# NUC122_v1 register map
File version: 1.0
Registers are 32-bit, read-write, reset 0x0 unless marked. A register's access mark holds for its fields unless they carry their own. Offsets are from the block's base; [hi:lo] are bit positions.

## RTC — RTC Register Map
Base 0x40008000
0x00 INIR — RTC Initiation Register
  [31:0] INIR — RTC Initiation. Read return current RTC active status. A write of 0xa5eb1357 to make RTC leaving reset state. When RTC block is powered on, RTC is in reset state. User has to write a number 0x a5eb1357 to INIR register to make RTC leave reset state. Once the INIR is written as 0xa5eb1357, the RTC will be in normal active state permanently.
    0=RTC is in reset state; 1=RTC is in normal active state
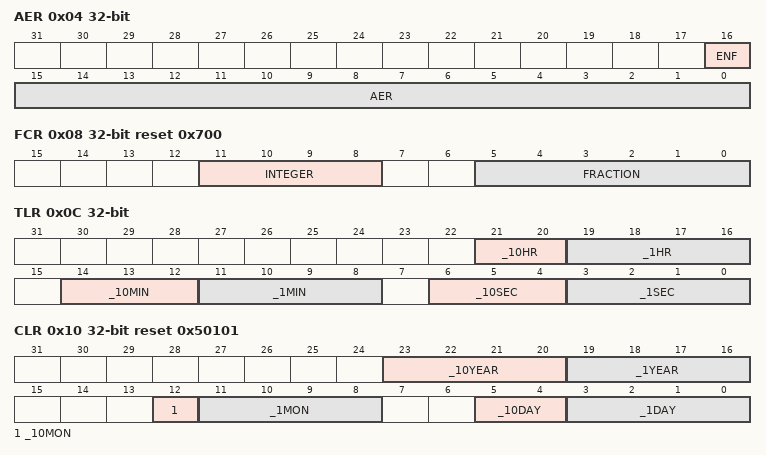
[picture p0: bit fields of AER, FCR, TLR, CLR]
0x04 AER — RTC Access Enable Register
  [16] ENF ro — RTC Register Access Enable Flag (Read only)
    0=RTC register read/write disable; 1=RTC register read/write enable
  [15:0] AER wo — RTC Register Access Enable Password (Write only). Writing 0xA965 to this register will enable RTC registers read/write access and keep 512 RTC clocks.
0x08 FCR reset 0x700 — Frequency Compensation Register
  [11:8] INTEGER — Integer Part
  [5:0] FRACTION — Fraction Part. Note: Digit in FCR must be expressed as hexadecimal number. Refer to 5.8.4.4 for the examples.
0x0C TLR — Time Loading Register
  [21:20] _10HR — 10-Hour Time Digit (0~2)
  [19:16] _1HR — 1-Hour Time Digit (0~9)
  [14:12] _10MIN — 10-Min Time Digit (0~5)
  [11:8] _1MIN — 1-Min Time Digit (0~9)
  [6:4] _10SEC — 10-Sec Time Digit (0~5)
  [3:0] _1SEC — 1-Sec Time Digit (0~9)
0x10 CLR reset 0x50101 — Calendar Loading Register
  [23:20] _10YEAR — 10-Year Calendar Digit (0~9)
  [19:16] _1YEAR — 1-Year Calendar Digit (0~9)
  [12] _10MON — 10-Month Calendar Digit (0~1)
  [11:8] _1MON — 1-Month Calendar Digit (0~9)
  [5:4] _10DAY — 10-Day Calendar Digit (0~3)
  [3:0] _1DAY — 1-Day Calendar Digit (0~9)
0x14 TSSR reset 0x1 — Time Scale Selection Register
  [0] _24hr_12hr — 24-Hour / 12-Hour Mode Selection
    0=select 12-hour time scale with AM and PM indication; 1=select 24-hour time scale
0x18 DWR reset 0x6 — Day of the Week Register
  [2:0] DWR
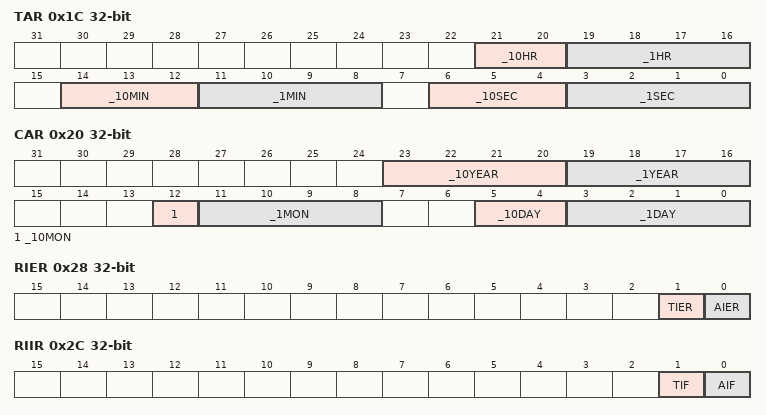
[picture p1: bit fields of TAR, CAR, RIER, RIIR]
0x1C TAR — Time Alarm Register
  [21:20] _10HR — 10-Hour Time Digit of Alarm Setting (0~2)
  [19:16] _1HR — 1-Hour Time Digit of Alarm Setting (0~9)
  [14:12] _10MIN — 10-Min Time Digit of Alarm Setting (0~5)
  [11:8] _1MIN — 1-Min Time Digit of Alarm Setting (0~9)
  [6:4] _10SEC — 10-Sec Time Digit of Alarm Setting (0~5)
  [3:0] _1SEC — 1-Sec Time Digit of Alarm Setting (0~9)
0x20 CAR — Calendar Alarm Register
  [23:20] _10YEAR — 10-Year Calendar Digit of Alarm Setting (0~9)
  [19:16] _1YEAR — 1-Year Calendar Digit of Alarm Setting (0~9)
  [12] _10MON — 10-Month Calendar Digit of Alarm Setting (0~1)
  [11:8] _1MON — 1-Month Calendar Digit of Alarm Setting (0~9)
  [5:4] _10DAY — 10-Day Calendar Digit of Alarm Setting (0~3)
  [3:0] _1DAY — 1-Day Calendar Digit of Alarm Setting (0~9)
0x24 LIR ro — RTC Leap Year Indication Register
  [0] LIR — Leap Year Indication REGISTER (Real only).
    0=It indicate that this year is not a leap year; 1=It indicate that this year is leap year
0x28 RIER — RTC Interrupt Enable Register
  [1] TIER — Time Tick Interrupt Enable
    0=RTC Time Tick Interrupt is disabled; 1=RTC Time Tick Interrupt is enabled
  [0] AIER — Alarm Interrupt Enable
    0=RTC Alarm Interrupt is disabled; 1=RTC Alarm Interrupt is enabled
0x2C RIIR — RTC Interrupt Indication Register
  [1] TIF — RTC Time Tick Interrupt Flag
    0=Indicates RTC Time Tick Interrupt condition never occurred; 1=Indicates RTC Time Tick Interrupt is requested if RIER.TIER=1
  [0] AIF — RTC Alarm Interrupt Flag
    0=Indicates RTC Alarm Interrupt condition never occurred; 1=Indicates RTC Alarm Interrupt is requested if RIER.AIER=1
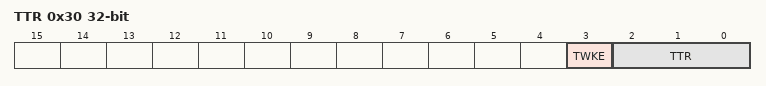
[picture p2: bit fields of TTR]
0x30 TTR — RTC Time Tick Register
  [3] TWKE — RTC Timer Wake-Up Function Enable Bit. If TWKE is set before chip is in power down mode, chip will be woken-up by RTC controller when a RTC Time Tick occurs, The chip can also be woken-up by alarm match occur. Note: Tick timer setting follows TTR[2:0] description.
    0=Disable RTC Timer wake-up function; 1=Enable RTC Timer wake-up function that chip can be woken-up from power down mode by Time Tick or Alarm Match
  [2:0] TTR — Time Tick Register
